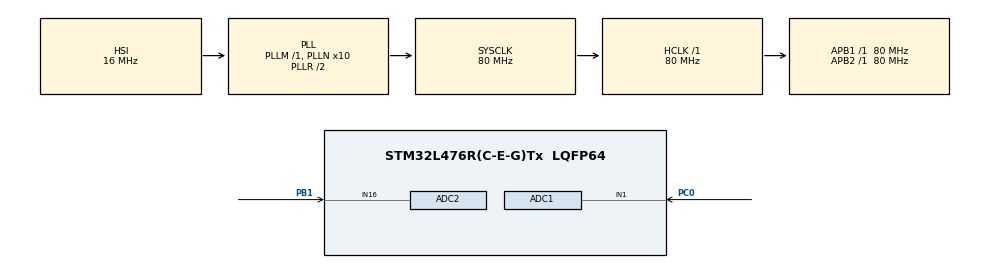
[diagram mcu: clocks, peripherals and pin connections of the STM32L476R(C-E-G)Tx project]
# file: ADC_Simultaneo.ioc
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ADC1.Channel-0\#ChannelRegularConversion=ADC_CHANNEL_1
ADC1.ClockPrescaler=ADC_CLOCK_ASYNC_DIV8
ADC1.ContinuousConvMode=ENABLE
ADC1.DMAAccessModeView=ENABLE
ADC1.DMAContinuousRequests=ENABLE
ADC1.Mode=ADC_DUALMODE_REGSIMULT
ADC1.NbrOfConversionFlag=1
ADC1.OffsetNumber-0\#ChannelRegularConversion=ADC_OFFSET_NONE
ADC1.Rank-0\#ChannelRegularConversion=1
ADC1.Resolution=ADC_RESOLUTION_10B
ADC1.SamplingTime-0\#ChannelRegularConversion=ADC_SAMPLETIME_640CYCLES_5
ADC1.TwoSamplingDelay=ADC_TWOSAMPLINGDELAY_8CYCLES
ADC1.master=1
ADC2.Channel-0\#ChannelRegularConversion=ADC_CHANNEL_16
ADC2.ClockPrescaler=ADC_CLOCK_ASYNC_DIV8
ADC2.DMAAccessModeView=ENABLE
ADC2.Mode=ADC_DUALMODE_REGSIMULT
ADC2.NbrOfConversionFlag=1
ADC2.OffsetNumber-0\#ChannelRegularConversion=ADC_OFFSET_NONE
ADC2.Rank-0\#ChannelRegularConversion=1
ADC2.Resolution=ADC_RESOLUTION_10B
ADC2.SamplingTime-0\#ChannelRegularConversion=ADC_SAMPLETIME_640CYCLES_5
ADC2.TwoSamplingDelay=ADC_TWOSAMPLINGDELAY_8CYCLES
Dma.ADC1.0.Direction=DMA_PERIPH_TO_MEMORY
Dma.ADC1.0.Instance=DMA1_Channel1
Dma.ADC1.0.MemDataAlignment=DMA_MDATAALIGN_WORD
Dma.ADC1.0.MemInc=DMA_MINC_ENABLE
Dma.ADC1.0.Mode=DMA_CIRCULAR
Dma.ADC1.0.PeriphDataAlignment=DMA_PDATAALIGN_WORD
Dma.ADC1.0.PeriphInc=DMA_PINC_DISABLE
Dma.ADC1.0.Priority=DMA_PRIORITY_LOW
Dma.Request0=ADC1
Mcu.Family=STM32L4
Mcu.Name=STM32L476R(C-E-G)Tx
Mcu.Package=LQFP64
NVIC.ADC1_2_IRQn=true\:0\:0\:false\:false\:true\:true\:true\:true
NVIC.DMA1_Channel1_IRQn=true\:0\:0\:false\:false\:true\:false\:true\:true
NVIC.PriorityGroup=NVIC_PRIORITYGROUP_4
PB1.Signal=ADCx_IN16
PC0.Signal=ADCx_IN1
ProjectManager.HeapSize=0x200
ProjectManager.StackSize=0x400
ProjectManager.TargetToolchain=STM32CubeIDE
RCC.ADCFreq_Value=64000000
RCC.AHBFreq_Value=80000000
RCC.APB1Freq_Value=80000000
RCC.APB1TimFreq_Value=80000000
RCC.APB2Freq_Value=80000000
RCC.APB2TimFreq_Value=80000000
RCC.CortexFreq_Value=80000000
RCC.HCLKFreq_Value=80000000
RCC.HSE_VALUE=8000000
RCC.HSI_VALUE=16000000
RCC.MSI_VALUE=4000000
RCC.PLLN=10
RCC.PLLSourceVirtual=RCC_PLLSOURCE_HSI
RCC.PREFETCH_ENABLE=1
RCC.SYSCLKFreq_VALUE=80000000
RCC.SYSCLKSource=RCC_SYSCLKSOURCE_PLLCLK
RCC.USBFreq_Value=64000000
RCC.VCOOutputFreq_Value=160000000
SH.ADCx_IN1.0=ADC1_IN1,IN1-Single-Ended
SH.ADCx_IN16.0=ADC2_IN16,IN16-Single-Ended
board=NUCLEO-L476RG

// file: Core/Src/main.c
/* USER CODE BEGIN Header */
/**
  ******************************************************************************
  * @file           : main.c
  * @brief          : Main program body
  ******************************************************************************
  * @attention
  *
  * Copyright (c) 2025 STMicroelectronics.
  * All rights reserved.
  *
  * This software is licensed under terms that can be found in the LICENSE file
  * in the root directory of this software component.
  * If no LICENSE file comes with this software, it is provided AS-IS.
  *
  ******************************************************************************
  */
/* USER CODE END Header */
#include "main.h"

/* USER CODE BEGIN Includes */

uint32_t datag; // dados recebidos do canal simultaneo pelo DMA
uint32_t adc1, adc2;

/* USER CODE END Includes */

ADC_HandleTypeDef hadc1;
ADC_HandleTypeDef hadc2;
DMA_HandleTypeDef hdma_adc1;

void SystemClock_Config(void);
void PeriphCommonClock_Config(void);
static void MX_GPIO_Init(void);
static void MX_DMA_Init(void);
static void MX_ADC1_Init(void);
static void MX_ADC2_Init(void);

int main(void)
{

  /* MCU Configuration--------------------------------------------------------*/

  /* Reset of all peripherals, Initializes the Flash interface and the Systick. */
  HAL_Init();

  /* Configure the system clock */
  SystemClock_Config();

  /* Configure the peripherals common clocks */
  PeriphCommonClock_Config();

  /* Initialize all configured peripherals */
  MX_GPIO_Init();
  MX_DMA_Init();
  MX_ADC1_Init();
  MX_ADC2_Init();
  /* USER CODE BEGIN 2 */

//  HAL_ADC_Start(&hadc2);
  HAL_ADCEx_MultiModeStart_DMA(&hadc1, &datag, 1); // start na conversao simultanea

  /* USER CODE END 2 */

  /* Infinite loop */
  while (1)
  {

    /* USER CODE BEGIN 3 */
	  adc1 = datag & 0x0000FFFF;
	  adc2 = datag >> 16;

	  HAL_Delay(100);
  }
  /* USER CODE END 3 */
}

void SystemClock_Config(void)
{
  RCC_OscInitTypeDef RCC_OscInitStruct = {0};
  RCC_ClkInitTypeDef RCC_ClkInitStruct = {0};

  /** Configure the main internal regulator output voltage
  */
  if (HAL_PWREx_ControlVoltageScaling(PWR_REGULATOR_VOLTAGE_SCALE1) != HAL_OK)
  {
    Error_Handler();
  }

  /** Initializes the RCC Oscillators according to the specified parameters
  * in the RCC_OscInitTypeDef structure.
  */
  RCC_OscInitStruct.OscillatorType = RCC_OSCILLATORTYPE_HSI;
  RCC_OscInitStruct.HSIState = RCC_HSI_ON;
  RCC_OscInitStruct.HSICalibrationValue = RCC_HSICALIBRATION_DEFAULT;
  RCC_OscInitStruct.PLL.PLLState = RCC_PLL_ON;
  RCC_OscInitStruct.PLL.PLLSource = RCC_PLLSOURCE_HSI;
  RCC_OscInitStruct.PLL.PLLM = 1;
  RCC_OscInitStruct.PLL.PLLN = 10;
  RCC_OscInitStruct.PLL.PLLP = RCC_PLLP_DIV7;
  RCC_OscInitStruct.PLL.PLLQ = RCC_PLLQ_DIV2;
  RCC_OscInitStruct.PLL.PLLR = RCC_PLLR_DIV2;
  if (HAL_RCC_OscConfig(&RCC_OscInitStruct) != HAL_OK)
  {
    Error_Handler();
  }

  /** Initializes the CPU, AHB and APB buses clocks
  */
  RCC_ClkInitStruct.ClockType = RCC_CLOCKTYPE_HCLK|RCC_CLOCKTYPE_SYSCLK
                              |RCC_CLOCKTYPE_PCLK1|RCC_CLOCKTYPE_PCLK2;
  RCC_ClkInitStruct.SYSCLKSource = RCC_SYSCLKSOURCE_PLLCLK;
  RCC_ClkInitStruct.AHBCLKDivider = RCC_SYSCLK_DIV1;
  RCC_ClkInitStruct.APB1CLKDivider = RCC_HCLK_DIV1;
  RCC_ClkInitStruct.APB2CLKDivider = RCC_HCLK_DIV1;

  if (HAL_RCC_ClockConfig(&RCC_ClkInitStruct, FLASH_LATENCY_4) != HAL_OK)
  {
    Error_Handler();
  }
}

void PeriphCommonClock_Config(void)
{
  RCC_PeriphCLKInitTypeDef PeriphClkInit = {0};

  /** Initializes the peripherals clock
  */
  PeriphClkInit.PeriphClockSelection = RCC_PERIPHCLK_ADC;
  PeriphClkInit.AdcClockSelection = RCC_ADCCLKSOURCE_PLLSAI1;
  PeriphClkInit.PLLSAI1.PLLSAI1Source = RCC_PLLSOURCE_HSI;
  PeriphClkInit.PLLSAI1.PLLSAI1M = 1;
  PeriphClkInit.PLLSAI1.PLLSAI1N = 8;
  PeriphClkInit.PLLSAI1.PLLSAI1P = RCC_PLLP_DIV7;
  PeriphClkInit.PLLSAI1.PLLSAI1Q = RCC_PLLQ_DIV2;
  PeriphClkInit.PLLSAI1.PLLSAI1R = RCC_PLLR_DIV2;
  PeriphClkInit.PLLSAI1.PLLSAI1ClockOut = RCC_PLLSAI1_ADC1CLK;
  if (HAL_RCCEx_PeriphCLKConfig(&PeriphClkInit) != HAL_OK)
  {
    Error_Handler();
  }
}

static void MX_ADC1_Init(void)
{

  ADC_MultiModeTypeDef multimode = {0};
  ADC_ChannelConfTypeDef sConfig = {0};

  /** Common config
  */
  hadc1.Instance = ADC1;
  hadc1.Init.ClockPrescaler = ADC_CLOCK_ASYNC_DIV8;
  hadc1.Init.Resolution = ADC_RESOLUTION_10B;
  hadc1.Init.DataAlign = ADC_DATAALIGN_RIGHT;
  hadc1.Init.ScanConvMode = ADC_SCAN_DISABLE;
  hadc1.Init.EOCSelection = ADC_EOC_SINGLE_CONV;
  hadc1.Init.LowPowerAutoWait = DISABLE;
  hadc1.Init.ContinuousConvMode = ENABLE;
  hadc1.Init.NbrOfConversion = 1;
  hadc1.Init.DiscontinuousConvMode = DISABLE;
  hadc1.Init.ExternalTrigConv = ADC_SOFTWARE_START;
  hadc1.Init.ExternalTrigConvEdge = ADC_EXTERNALTRIGCONVEDGE_NONE;
  hadc1.Init.DMAContinuousRequests = ENABLE;
  hadc1.Init.Overrun = ADC_OVR_DATA_PRESERVED;
  hadc1.Init.OversamplingMode = DISABLE;
  if (HAL_ADC_Init(&hadc1) != HAL_OK)
  {
    Error_Handler();
  }

  /** Configure the ADC multi-mode
  */
  multimode.Mode = ADC_DUALMODE_REGSIMULT;
  multimode.DMAAccessMode = ADC_DMAACCESSMODE_12_10_BITS;
  multimode.TwoSamplingDelay = ADC_TWOSAMPLINGDELAY_8CYCLES;
  if (HAL_ADCEx_MultiModeConfigChannel(&hadc1, &multimode) != HAL_OK)
  {
    Error_Handler();
  }

  /** Configure Regular Channel
  */
  sConfig.Channel = ADC_CHANNEL_1;
  sConfig.Rank = ADC_REGULAR_RANK_1;
  sConfig.SamplingTime = ADC_SAMPLETIME_640CYCLES_5;
  sConfig.SingleDiff = ADC_SINGLE_ENDED;
  sConfig.OffsetNumber = ADC_OFFSET_NONE;
  sConfig.Offset = 0;
  if (HAL_ADC_ConfigChannel(&hadc1, &sConfig) != HAL_OK)
  {
    Error_Handler();
  }

}

static void MX_ADC2_Init(void)
{

  ADC_ChannelConfTypeDef sConfig = {0};

  /** Common config
  */
  hadc2.Instance = ADC2;
  hadc2.Init.ClockPrescaler = ADC_CLOCK_ASYNC_DIV8;
  hadc2.Init.Resolution = ADC_RESOLUTION_10B;
  hadc2.Init.DataAlign = ADC_DATAALIGN_RIGHT;
  hadc2.Init.ScanConvMode = ADC_SCAN_DISABLE;
  hadc2.Init.EOCSelection = ADC_EOC_SINGLE_CONV;
  hadc2.Init.LowPowerAutoWait = DISABLE;
  hadc2.Init.ContinuousConvMode = ENABLE;
  hadc2.Init.NbrOfConversion = 1;
  hadc2.Init.DiscontinuousConvMode = DISABLE;
  hadc2.Init.DMAContinuousRequests = DISABLE;
  hadc2.Init.Overrun = ADC_OVR_DATA_PRESERVED;
  hadc2.Init.OversamplingMode = DISABLE;
  if (HAL_ADC_Init(&hadc2) != HAL_OK)
  {
    Error_Handler();
  }

  /** Configure Regular Channel
  */
  sConfig.Channel = ADC_CHANNEL_16;
  sConfig.Rank = ADC_REGULAR_RANK_1;
  sConfig.SamplingTime = ADC_SAMPLETIME_640CYCLES_5;
  sConfig.SingleDiff = ADC_SINGLE_ENDED;
  sConfig.OffsetNumber = ADC_OFFSET_NONE;
  sConfig.Offset = 0;
  if (HAL_ADC_ConfigChannel(&hadc2, &sConfig) != HAL_OK)
  {
    Error_Handler();
  }

}

static void MX_DMA_Init(void)
{

  /* DMA controller clock enable */
  __HAL_RCC_DMA1_CLK_ENABLE();

  /* DMA interrupt init */
  /* DMA1_Channel1_IRQn interrupt configuration */
  HAL_NVIC_SetPriority(DMA1_Channel1_IRQn, 0, 0);
  HAL_NVIC_EnableIRQ(DMA1_Channel1_IRQn);

}

static void MX_GPIO_Init(void)
{

  /* GPIO Ports Clock Enable */
  __HAL_RCC_GPIOC_CLK_ENABLE();
  __HAL_RCC_GPIOB_CLK_ENABLE();

}

void Error_Handler(void)
{
  __disable_irq();
  while (1)
  {
  }
}
